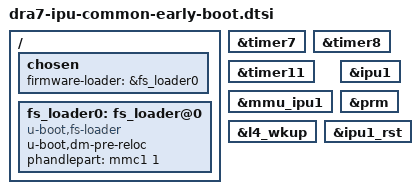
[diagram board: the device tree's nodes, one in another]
// SPDX-License-Identifier: GPL-2.0+
/*
 * Copyright (C) 2019 Texas Instruments Incorporated - http://www.ti.com/
 */

/ {
	chosen {
		firmware-loader = &fs_loader0;
	};

	fs_loader0: fs_loader@0 {
		u-boot,dm-pre-reloc;
		compatible = "u-boot,fs-loader";
		phandlepart = <&mmc1 1>;
	};
};

&timer7 {
	u-boot,dm-spl;
};

&timer8 {
	u-boot,dm-spl;
};

&timer11 {
	u-boot,dm-spl;
};

&mmu_ipu1 {
	u-boot,dm-spl;
};

&ipu1 {
	status = "okay";
	u-boot,dm-spl;
};

&l4_wkup {
	u-boot,dm-spl;
};

&prm {
	u-boot,dm-spl;
};

&ipu1_rst {
	u-boot,dm-spl;
};
